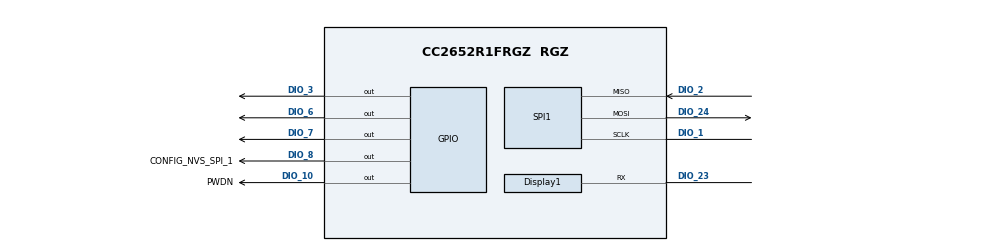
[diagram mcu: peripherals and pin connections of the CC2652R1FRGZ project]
/**
 * @cliArgs --device "CC2652R1FRGZ" --package "RGZ" --part "Default" --product "simplelink_cc13x2_26x2_sdk@4.30.00.54"
 * @versions {"data":"2020090214","timestamp":"2020090214","tool":"1.6.0+1543","templates":"2020090214"}
 */

/**
 * Import the modules used in this configuration.
 */
const ble         = scripting.addModule("/ti/ble5stack/ble");
const CCFG        = scripting.addModule("/ti/devices/CCFG");
const rfdesign    = scripting.addModule("/ti/devices/radioconfig/rfdesign");
const Display     = scripting.addModule("/ti/display/Display");
const Display1    = Display.addInstance();
const AESCCM      = scripting.addModule("/ti/drivers/AESCCM");
const AESCCM1     = AESCCM.addInstance();
const AESCTRDRBG  = scripting.addModule("/ti/drivers/AESCTRDRBG");
const AESCTRDRBG1 = AESCTRDRBG.addInstance();
const AESECB      = scripting.addModule("/ti/drivers/AESECB");
const AESECB1     = AESECB.addInstance();
const ECDH        = scripting.addModule("/ti/drivers/ECDH");
const ECDH1       = ECDH.addInstance();
const GPIO        = scripting.addModule("/ti/drivers/GPIO");
const GPIO1       = GPIO.addInstance();
const GPIO2       = GPIO.addInstance();
const GPIO3       = GPIO.addInstance();
const GPIO4       = GPIO.addInstance();
const GPIO5       = GPIO.addInstance();
const NVS         = scripting.addModule("/ti/drivers/NVS");
const NVS1        = NVS.addInstance();
const NVS2        = NVS.addInstance();
const Power       = scripting.addModule("/ti/drivers/Power");
const RF          = scripting.addModule("/ti/drivers/RF");
const RTOS        = scripting.addModule("/ti/drivers/RTOS");
const SPI         = scripting.addModule("/ti/drivers/SPI", {}, false);
const SPI1        = SPI.addInstance();
const TRNG        = scripting.addModule("/ti/drivers/TRNG");
const TRNG1       = TRNG.addInstance();

/**
 * Write custom configuration values to the imported modules.
 */
ble.lockProject                                     = true;
ble.deviceName                                      = "Project Zero";
ble.addressMode                                     = "ADDRMODE_PUBLIC";
ble.disableDisplayModule                            = true;
ble.uartLog                                         = true;
ble.maxPDUSize                                      = 251;
ble.maxConnNum                                      = 2;
ble.numOfAdvSets                                    = 1;
ble.numOfDefAdvSets                                 = 1;
ble.frontEndMode                                    = "RF_FE_SINGLE_ENDED_RFP";
ble.biasConfiguration                               = "RF_FE_EXT_BIAS";
ble.defaultTxPower                                  = "HCI_EXT_TX_POWER_2_DBM";
ble.powerMamagement                                 = false;
ble.extendedStackSettings                           = "MASTER_GUARD_TIME_ENABLE";
ble.radioConfig.codeExportConfig.$name              = "ti_devices_radioconfig_code_export_param0";
ble.connUpdateParamsPeripheral.$name                = "ti_ble5stack_general_ble_conn_update_params0";
ble.connUpdateParamsPeripheral.reqConnTo            = 2000;
ble.connUpdateParamsPeripheral.reqMaxConnInt        = 45;
ble.connUpdateParamsPeripheral.reqMinConnInt        = 15;
ble.advSet1.$name                                   = "ti_ble5stack_broadcaster_advertisement_set0";
ble.advSet1.advParam1.$name                         = "ti_ble5stack_broadcaster_advertisement_params0";
ble.advSet1.advData1.$name                          = "ti_ble5stack_broadcaster_advertisement_data0";
ble.advSet1.advData1.GAP_ADTYPE_FLAGS               = true;
ble.advSet1.advData1.advertisingFlags               = ["GAP_ADTYPE_FLAGS_BREDR_NOT_SUPPORTED","GAP_ADTYPE_FLAGS_GENERAL"];
ble.advSet1.advData1.GAP_ADTYPE_LOCAL_NAME_COMPLETE = true;
ble.advSet1.advData1.completeLocalName              = "Project Zero";
ble.advSet1.scanRes1.$name                          = "ti_ble5stack_broadcaster_advertisement_data1";
ble.advSet1.scanRes1.GAP_ADTYPE_128BIT_MORE         = true;
ble.advSet1.scanRes1.numOfUUIDs128More              = 1;
ble.advSet1.scanRes1.UUID0128More                   = system.utils.bigInt("B000405104101100F0",16);

CCFG.enableCodeGeneration = false;
CCFG.ccfgTemplate.$name   = "ti_devices_CCFGTemplateInit0";

rfdesign.fe24g = "XS_RFP";

Display1.$name                    = "CONFIG_Display_0";
Display1.enableANSI               = true;
Display1.uartBufferSize           = 128;
Display1.uart.$name               = "CONFIG_DISPLAY_UART";
Display1.uart.dataDirection       = "Receive Only";
Display1.uart.rxPinInstance.$name = "CONFIG_PIN_UART_RX";
Display1.uart.uart.rxPin.$assign  = "DIO_23";

AESCCM1.$name = "CONFIG_AESCCM0";

AESCTRDRBG1.$name              = "CONFIG_AESCTRDRBG_0";
AESCTRDRBG1.aesctrObject.$name = "CONFIG_AESCTR_0";

AESECB1.$name = "CONFIG_AESECB0";

ECDH1.$name = "CONFIG_ECDH0";

GPIO1.pull              = "Pull Up";
GPIO1.interruptTrigger  = "Falling Edge";
GPIO1.mode              = "Dynamic";
GPIO1.$name             = "CONFIG_GPIO_BTN1";
GPIO1.gpioPin.$assign   = "DIO_3";
GPIO1.pinInstance.$name = "CONFIG_PIN_BTN1";

GPIO2.pull              = "Pull Up";
GPIO2.interruptTrigger  = "Falling Edge";
GPIO2.mode              = "Dynamic";
GPIO2.$name             = "CONFIG_GPIO_BTN2";
GPIO2.pinInstance.$name = "CONFIG_PIN_BTN2";

GPIO3.mode              = "Dynamic";
GPIO3.$name             = "CONFIG_GPIO_RLED";
GPIO3.gpioPin.$assign   = "DIO_6";
GPIO3.pinInstance.$name = "CONFIG_PIN_RLED";

GPIO4.mode              = "Dynamic";
GPIO4.$name             = "CONFIG_GPIO_GLED";
GPIO4.gpioPin.$assign   = "DIO_7";
GPIO4.pinInstance.$name = "CONFIG_PIN_GLED";

GPIO5.$name             = "PWDN";
GPIO5.mode              = "Dynamic";
GPIO5.gpioPin.$assign   = "DIO_10";
GPIO5.pinInstance.$name = "CONFIG_PIN_4";

NVS1.$name                    = "CONFIG_NVSINTERNAL";
NVS1.internalFlash.$name      = "ti_drivers_nvs_NVSCC26XX0";
NVS1.internalFlash.regionBase = 0x48000;
NVS1.internalFlash.regionSize = 0x4000;

NVS2.nvsType                        = "External";
NVS2.$name                          = "CONFIG_NVSEXTERNAL";
NVS2.externalFlash.$name            = "ti_drivers_nvs_NVSSPI25X0";
NVS2.externalFlash.regionSize       = 0x100000;
NVS2.externalFlash.verifyBufferSize = 64;

Power.enablePolicy = false;

TRNG1.$name = "CONFIG_TRNG_0";

const NVSSPI25XDevice                                      = scripting.addModule("/ti/drivers/nvs/NVSSPI25XDevice", {}, false);
const NVSSPI25XDevice1                                     = NVSSPI25XDevice.addInstance({}, false);
NVSSPI25XDevice1.$name                                     = "CONFIG_NVS_SPI_1";
NVS2.externalFlash.spiFlashDevice                          = NVSSPI25XDevice1;
NVSSPI25XDevice1.slaveSelectGpioInstance.$name             = "CONFIG_GPIO_1";
NVSSPI25XDevice1.slaveSelectGpioInstance.gpioPin.$assign   = "DIO_8";
NVSSPI25XDevice1.slaveSelectGpioInstance.pinInstance.$name = "CONFIG_PIN_5";

SPI1.$name                         = "CONFIG_SPI_0";
NVSSPI25XDevice1.sharedSpiInstance = SPI1;
SPI1.defaultTxBufferValue          = "0";
SPI1.spi.$assign                   = "SSI0";
SPI1.spi.sclkPin.$assign           = "DIO_1";
SPI1.spi.misoPin.$assign           = "DIO_2";
SPI1.spi.mosiPin.$assign           = "DIO_24";
SPI1.sclkPinInstance.$name         = "CONFIG_PIN_1";
SPI1.misoPinInstance.$name         = "CONFIG_PIN_2";
SPI1.mosiPinInstance.$name         = "CONFIG_PIN_3";

/**
 * Pinmux solution for unlocked pins/peripherals. This ensures that minor changes to the automatic solver in a future
 * version of the tool will not impact the pinmux you originally saw.  These lines can be completely deleted in order to
 * re-solve from scratch.
 */
Display1.uart.uart.$suggestSolution    = "UART1";
GPIO2.gpioPin.$suggestSolution         = "DIO_0";
SPI1.spi.dmaRxChannel.$suggestSolution = "DMA_CH3";
SPI1.spi.dmaTxChannel.$suggestSolution = "DMA_CH4";
